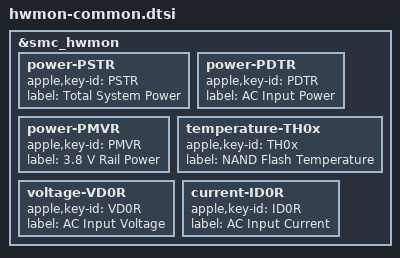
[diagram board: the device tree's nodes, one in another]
// SPDX-License-Identifier: GPL-2.0+ OR MIT
/*
 * hwmon sensors expected on all systems
 *
 * Copyright The Asahi Linux Contributors
 */

&smc_hwmon {
	power-PSTR {
		apple,key-id = "PSTR";
		label = "Total System Power";
	};

	power-PDTR {
		apple,key-id = "PDTR";
		label = "AC Input Power";
	};

	power-PMVR {
		apple,key-id = "PMVR";
		label = "3.8 V Rail Power";
	};

	temperature-TH0x {
		apple,key-id = "TH0x";
		label = "NAND Flash Temperature";
	};

	voltage-VD0R {
		apple,key-id = "VD0R";
		label = "AC Input Voltage";
	};

	current-ID0R {
		apple,key-id = "ID0R";
		label = "AC Input Current";
	};
};
